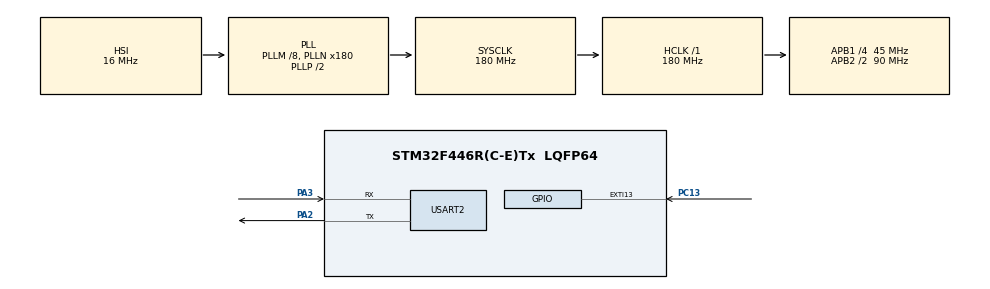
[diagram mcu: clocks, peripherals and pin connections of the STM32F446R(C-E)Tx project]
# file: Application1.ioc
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Mcu.Family=STM32F4
RCC.CortexFreq_Value=180000000
PC13.Signal=GPXTI13
RCC.APB1CLKDivider=RCC_HCLK_DIV4
RCC.SYSCLKSource=RCC_SYSCLKSOURCE_PLLCLK
ProjectManager.StackSize=0x400
PA13.Signal=SYS_JTMS-SWDIO
PA3.Mode=Asynchronous
ProjectManager.TargetToolchain=STM32CubeIDE
RCC.HCLKFreq_Value=180000000
RCC.APB2TimFreq_Value=180000000
RCC.USBFreq_Value=180000000
RCC.AHBFreq_Value=180000000
NVIC.EXTI15_10_IRQn=true\:0\:0\:false\:false\:true\:true\:true
board=custom
RCC.VCOOutputFreq_Value=360000000
RCC.APB2Freq_Value=90000000
PA14.Mode=Serial_Wire
PC13.GPIO_PuPd=GPIO_PULLUP
PA13.Mode=Serial_Wire
Mcu.Name=STM32F446R(C-E)Tx
PA2.Signal=USART2_TX
RCC.SYSCLKFreq_VALUE=180000000
Mcu.Package=LQFP64
PC13.GPIO_ModeDefaultEXTI=GPIO_MODE_IT_FALLING
USART2.VirtualMode=VM_ASYNC
PA14.Signal=SYS_JTCK-SWCLK
ProjectManager.HeapSize=0x200
NVIC.PriorityGroup=NVIC_PRIORITYGROUP_4
RCC.APB2CLKDivider=RCC_HCLK_DIV2
RCC.PLLM=8
RCC.PLLN=180
RCC.APB1TimFreq_Value=90000000
PA2.Mode=Asynchronous
RCC.APB1Freq_Value=45000000
PA3.Signal=USART2_RX

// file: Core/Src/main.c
/* USER CODE BEGIN Header */
/**
  ******************************************************************************
  * @file           : main.c
  * @brief          : Main program body
  ******************************************************************************
  * @attention
  *
  * <h2><center>&copy; Copyright (c) 2026 STMicroelectronics.
  * All rights reserved.</center></h2>
  *
  * This software component is licensed by ST under BSD 3-Clause license,
  * the "License"; You may not use this file except in compliance with the
  * License. You may obtain a copy of the License at:
  *                        opensource.org/licenses/BSD-3-Clause
  *
  ******************************************************************************
  */
/* USER CODE END Header */
#include "main.h"

/* USER CODE BEGIN Includes */
#include "flash_layout.h"
#include "app_header.h"
/* USER CODE END Includes */

UART_HandleTypeDef huart2;

void SystemClock_Config(void);
static void MX_GPIO_Init(void);
static void MX_USART2_UART_Init(void);

/* USER CODE BEGIN 0 */
__attribute__((section(".header"))) const app_header_t app_header =
{
    .ota_flag = 0,
    .magic    = 0xABCDEFAB,
    .size     = 10368,//10368
    .crc      = 0x3139620D,//0x3139620D
    .version  = 0
};

volatile int isbuttonpressed=0;

void HAL_GPIO_EXTI_Callback(uint16_t GPIO_Pin)
{
    isbuttonpressed=1;
}

/* USER CODE END 0 */

int main(void)
{

  /* MCU Configuration--------------------------------------------------------*/

  /* Reset of all peripherals, Initializes the Flash interface and the Systick. */
  HAL_Init();

  /* USER CODE BEGIN Init */
  SCB->VTOR = APP_START_ADDR;
  __enable_irq();

  /* USER CODE END Init */

  /* Configure the system clock */
  SystemClock_Config();

  /* Initialize all configured peripherals */
  MX_GPIO_Init();
  MX_USART2_UART_Init();
  /* USER CODE BEGIN 2 */
  HAL_UART_Transmit(&huart2, (uint8_t *)"inside Test application!!\r\n", 26, 100);

  /* USER CODE END 2 */

  /* Infinite loop */
  while (1)
  {

    /* USER CODE BEGIN 3 */
	 HAL_UART_Transmit(&huart2, (uint8_t *)"application routine before OTA!!\r\n", 32, 100);
	 HAL_Delay(1000);
	 if(isbuttonpressed==1){
		 HAL_Delay(250);
		 enable_ota_request();
	 }

  }
  /* USER CODE END 3 */
}

void SystemClock_Config(void)
{
  RCC_OscInitTypeDef RCC_OscInitStruct = {0};
  RCC_ClkInitTypeDef RCC_ClkInitStruct = {0};

  /** Configure the main internal regulator output voltage
  */
  __HAL_RCC_PWR_CLK_ENABLE();
  __HAL_PWR_VOLTAGESCALING_CONFIG(PWR_REGULATOR_VOLTAGE_SCALE1);
  /** Initializes the RCC Oscillators according to the specified parameters
  * in the RCC_OscInitTypeDef structure.
  */
  RCC_OscInitStruct.OscillatorType = RCC_OSCILLATORTYPE_HSI;
  RCC_OscInitStruct.HSIState = RCC_HSI_ON;
  RCC_OscInitStruct.HSICalibrationValue = RCC_HSICALIBRATION_DEFAULT;
  RCC_OscInitStruct.PLL.PLLState = RCC_PLL_ON;
  RCC_OscInitStruct.PLL.PLLSource = RCC_PLLSOURCE_HSI;
  RCC_OscInitStruct.PLL.PLLM = 8;
  RCC_OscInitStruct.PLL.PLLN = 180;
  RCC_OscInitStruct.PLL.PLLP = RCC_PLLP_DIV2;
  RCC_OscInitStruct.PLL.PLLQ = 2;
  RCC_OscInitStruct.PLL.PLLR = 2;
  if (HAL_RCC_OscConfig(&RCC_OscInitStruct) != HAL_OK)
  {
    Error_Handler();
  }
  /** Activate the Over-Drive mode
  */
  if (HAL_PWREx_EnableOverDrive() != HAL_OK)
  {
    Error_Handler();
  }
  /** Initializes the CPU, AHB and APB buses clocks
  */
  RCC_ClkInitStruct.ClockType = RCC_CLOCKTYPE_HCLK|RCC_CLOCKTYPE_SYSCLK
                              |RCC_CLOCKTYPE_PCLK1|RCC_CLOCKTYPE_PCLK2;
  RCC_ClkInitStruct.SYSCLKSource = RCC_SYSCLKSOURCE_PLLCLK;
  RCC_ClkInitStruct.AHBCLKDivider = RCC_SYSCLK_DIV1;
  RCC_ClkInitStruct.APB1CLKDivider = RCC_HCLK_DIV4;
  RCC_ClkInitStruct.APB2CLKDivider = RCC_HCLK_DIV2;

  if (HAL_RCC_ClockConfig(&RCC_ClkInitStruct, FLASH_LATENCY_5) != HAL_OK)
  {
    Error_Handler();
  }
}

static void MX_USART2_UART_Init(void)
{

  huart2.Instance = USART2;
  huart2.Init.BaudRate = 115200;
  huart2.Init.WordLength = UART_WORDLENGTH_8B;
  huart2.Init.StopBits = UART_STOPBITS_1;
  huart2.Init.Parity = UART_PARITY_NONE;
  huart2.Init.Mode = UART_MODE_TX_RX;
  huart2.Init.HwFlowCtl = UART_HWCONTROL_NONE;
  huart2.Init.OverSampling = UART_OVERSAMPLING_16;
  if (HAL_UART_Init(&huart2) != HAL_OK)
  {
    Error_Handler();
  }

}

static void MX_GPIO_Init(void)
{
  GPIO_InitTypeDef GPIO_InitStruct = {0};

  /* GPIO Ports Clock Enable */
  __HAL_RCC_GPIOC_CLK_ENABLE();
  __HAL_RCC_GPIOA_CLK_ENABLE();

  /*Configure GPIO pin : PC13 */
  GPIO_InitStruct.Pin = GPIO_PIN_13;
  GPIO_InitStruct.Mode = GPIO_MODE_IT_FALLING;
  GPIO_InitStruct.Pull = GPIO_PULLUP;
  HAL_GPIO_Init(GPIOC, &GPIO_InitStruct);

  /* EXTI interrupt init*/
  HAL_NVIC_SetPriority(EXTI15_10_IRQn, 0, 0);
  HAL_NVIC_EnableIRQ(EXTI15_10_IRQn);

}

void Error_Handler(void)
{
  __disable_irq();
  while (1)
  {
  }
}

/************************ (C) COPYRIGHT STMicroelectronics *****END OF FILE****/
